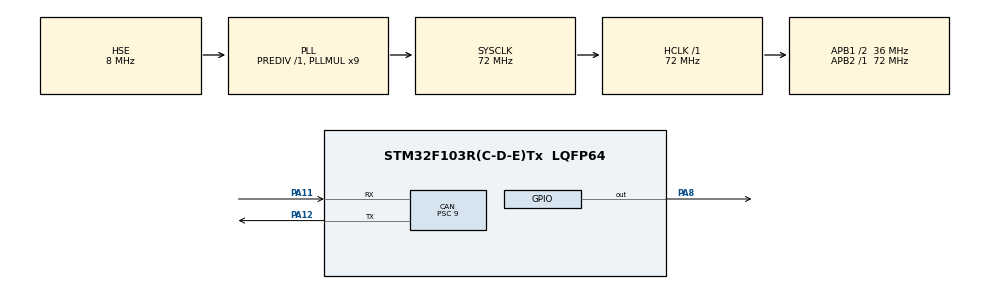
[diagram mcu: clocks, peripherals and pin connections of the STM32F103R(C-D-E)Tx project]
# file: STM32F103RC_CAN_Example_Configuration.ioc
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CAN.ABOM=ENABLE
CAN.AWUM=ENABLE
CAN.BS1=CAN_BS1_5TQ
CAN.BS2=CAN_BS2_2TQ
CAN.CalculateBaudRate=500000
CAN.CalculateTimeBit=2000
CAN.CalculateTimeQuantum=250.0
CAN.NART=ENABLE
CAN.Prescaler=9
Mcu.Family=STM32F1
Mcu.Name=STM32F103R(C-D-E)Tx
Mcu.Package=LQFP64
NVIC.PriorityGroup=NVIC_PRIORITYGROUP_4
NVIC.USB_LP_CAN1_RX0_IRQn=true\:0\:0\:false\:false\:true\:true\:true\:true
PA11.Mode=CAN_Activate
PA11.Signal=CAN_RX
PA12.Mode=CAN_Activate
PA12.Signal=CAN_TX
PA13.Mode=Trace_Asynchronous_SW
PA13.Signal=SYS_JTMS-SWDIO
PA14.Mode=Trace_Asynchronous_SW
PA14.Signal=SYS_JTCK-SWCLK
PA8.Signal=GPIO_Output
PB3.Mode=Trace_Asynchronous_SW
PB3.Signal=SYS_JTDO-TRACESWO
PD0-OSC_IN.Mode=HSE-External-Oscillator
PD0-OSC_IN.Signal=RCC_OSC_IN
PD1-OSC_OUT.Mode=HSE-External-Oscillator
PD1-OSC_OUT.Signal=RCC_OSC_OUT
ProjectManager.HeapSize=0x200
ProjectManager.StackSize=0x400
ProjectManager.TargetToolchain=MDK-ARM V5.32
RCC.AHBFreq_Value=72000000
RCC.APB1CLKDivider=RCC_HCLK_DIV2
RCC.APB1Freq_Value=36000000
RCC.APB1TimFreq_Value=72000000
RCC.APB2Freq_Value=72000000
RCC.APB2TimFreq_Value=72000000
RCC.HCLKFreq_Value=72000000
RCC.PLLMUL=RCC_PLL_MUL9
RCC.PLLSourceVirtual=RCC_PLLSOURCE_HSE
RCC.SYSCLKFreq_VALUE=72000000
RCC.SYSCLKSource=RCC_SYSCLKSOURCE_PLLCLK
RCC.USBFreq_Value=72000000
board=custom

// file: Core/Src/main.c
/* USER CODE BEGIN Header */
/**
  ******************************************************************************
  * @file           : main.c
  * @brief          : Main program body
  ******************************************************************************
  * @attention
  *
  * Copyright (c) 2023 STMicroelectronics.
  * All rights reserved.
  *
  * This software is licensed under terms that can be found in the LICENSE file
  * in the root directory of this software component.
  * If no LICENSE file comes with this software, it is provided AS-IS.
  *
  ******************************************************************************
  */
/* USER CODE END Header */
#include "main.h"

/* USER CODE BEGIN Includes */
#include"CAN_SignalHandler.h"
CAN_TxHeaderTypeDef   TxHeader;

uint8_t               TxData[8] = {0,0,0,0,0,0,0,0};

uint32_t              TxMailbox;

CAN_RxHeaderTypeDef   RxHeader;

CAN_FilterTypeDef	  canfil;

uint8_t               RxData[8] = {0,0,0,0,0,0,0,0};

uint16_t datacheck[75]={0};
uint16_t previousData[75]={0};
uint16_t data1,data2,data3;
/* USER CODE END Includes */

CAN_HandleTypeDef hcan;

/* USER CODE BEGIN PV */
void HAL_CAN_RxFifo0MsgPendingCallback(CAN_HandleTypeDef *hcan1)
{

//		HAL_CAN_GetRxMessage(hcan1, CAN_RX_FIFO0, &RxHeader, RxData);
//		for (int i = 0; i < 8; i++) {
//			TxData[i]=RxData[i];
//		}
//		HAL_CAN_AddTxMessage(&hcan, &TxHeader, TxData, &TxMailbox);
//		HAL_GPIO_TogglePin(GPIOA, GPIO_PIN_8);

	HAL_CAN_GetRxMessage(hcan1, CAN_RX_FIFO0, &RxHeader, RxData);
	int8_t msg_Idx = MessageIdx(RxHeader.StdId);
	StoreSignal(msg_Idx, RxData);
	//HAL_CAN_AddTxMessage(&hcan, &TxHeader, TxData, &TxMailbox);
}

/* USER CODE END PV */

void SystemClock_Config(void);
static void MX_GPIO_Init(void);
static void MX_CAN_Init(void);

int main(void)
{
  /* USER CODE BEGIN 1 */
	/*Filter congiguration*/
	canfil.FilterBank = 0;
	canfil.FilterMode = CAN_FILTERMODE_IDMASK;
	canfil.FilterFIFOAssignment = CAN_RX_FIFO0;
	canfil.FilterIdHigh = 0;
	canfil.FilterIdLow = 0;
	canfil.FilterMaskIdHigh = 0;
	canfil.FilterMaskIdLow = 0;
	canfil.FilterScale = CAN_FILTERSCALE_32BIT;
	canfil.FilterActivation = ENABLE;
	canfil.SlaveStartFilterBank = 14;
	/*TxHeader Configuration*/
	TxHeader.IDE = CAN_ID_STD;
	TxHeader.StdId = 0x446;
	TxHeader.RTR = CAN_RTR_DATA;
	TxHeader.DLC = 8;
	TxHeader.TransmitGlobalTime = DISABLE;

  /* USER CODE END 1 */

  /* MCU Configuration--------------------------------------------------------*/

  /* Reset of all peripherals, Initializes the Flash interface and the Systick. */
  HAL_Init();

  /* Configure the system clock */
  SystemClock_Config();

  /* Initialize all configured peripherals */
  MX_GPIO_Init();
  MX_CAN_Init();
  /* USER CODE BEGIN 2 */
  HAL_CAN_ConfigFilter(&hcan,&canfil); //Initialize CAN Filter
  HAL_CAN_Start(&hcan);
  HAL_CAN_ActivateNotification(&hcan,CAN_IT_RX_FIFO0_MSG_PENDING);// Initialize
  /* USER CODE END 2 */

  /* Infinite loop */
  /* USER CODE BEGIN WHILE */
  while (1)
  {
		//ReadCanSignal8(69,&datacheck[2]);

		//ReadCanSignal8(70,&datacheck[3]);

		//ReadCanSignal8(71,&datacheck[4]);

//		ReadCanSignal8(71,&data3);
//		HAL_Delay(50);
//		ReadCanSignal8(69,&data1);
//		HAL_Delay(50);
//		ReadCanSignal8(70,&data2);
//		HAL_Delay(50);
		for(int i =0;i<75;i++)
		{
			ReadCanSignal8(i+1,&datacheck[i]);
			HAL_Delay(50);
		}

		for(int i =0;i<75;i++)
		{
			if(previousData[i] != datacheck[i])
			{
				TxHeader.StdId = getSignal_MessageId(i)+0x11;
				getSignalMessageData(i, TxData,datacheck[i]);
				HAL_CAN_AddTxMessage(&hcan, &TxHeader, TxData, &TxMailbox);
				HAL_Delay(50);
				previousData[i] = datacheck[i];
			}
		}

//	 	 HAL_GPIO_TogglePin(GPIOA,GPIO_PIN_8);
//	 	 HAL_CAN_AddTxMessage(&hcan, &TxHeader, TxData, &TxMailbox);
//	 	 HAL_Delay(500);

    /* USER CODE END WHILE */

  }
}

void SystemClock_Config(void)
{
  RCC_OscInitTypeDef RCC_OscInitStruct = {0};
  RCC_ClkInitTypeDef RCC_ClkInitStruct = {0};

  /** Initializes the RCC Oscillators according to the specified parameters
  * in the RCC_OscInitTypeDef structure.
  */
  RCC_OscInitStruct.OscillatorType = RCC_OSCILLATORTYPE_HSE;
  RCC_OscInitStruct.HSEState = RCC_HSE_ON;
  RCC_OscInitStruct.HSEPredivValue = RCC_HSE_PREDIV_DIV1;
  RCC_OscInitStruct.HSIState = RCC_HSI_ON;
  RCC_OscInitStruct.PLL.PLLState = RCC_PLL_ON;
  RCC_OscInitStruct.PLL.PLLSource = RCC_PLLSOURCE_HSE;
  RCC_OscInitStruct.PLL.PLLMUL = RCC_PLL_MUL9;
  if (HAL_RCC_OscConfig(&RCC_OscInitStruct) != HAL_OK)
  {
    Error_Handler();
  }

  /** Initializes the CPU, AHB and APB buses clocks
  */
  RCC_ClkInitStruct.ClockType = RCC_CLOCKTYPE_HCLK|RCC_CLOCKTYPE_SYSCLK
                              |RCC_CLOCKTYPE_PCLK1|RCC_CLOCKTYPE_PCLK2;
  RCC_ClkInitStruct.SYSCLKSource = RCC_SYSCLKSOURCE_PLLCLK;
  RCC_ClkInitStruct.AHBCLKDivider = RCC_SYSCLK_DIV1;
  RCC_ClkInitStruct.APB1CLKDivider = RCC_HCLK_DIV2;
  RCC_ClkInitStruct.APB2CLKDivider = RCC_HCLK_DIV1;

  if (HAL_RCC_ClockConfig(&RCC_ClkInitStruct, FLASH_LATENCY_2) != HAL_OK)
  {
    Error_Handler();
  }
}

static void MX_CAN_Init(void)
{

  hcan.Instance = CAN1;
  hcan.Init.Prescaler = 9;
  hcan.Init.Mode = CAN_MODE_NORMAL;
  hcan.Init.SyncJumpWidth = CAN_SJW_1TQ;
  hcan.Init.TimeSeg1 = CAN_BS1_5TQ;
  hcan.Init.TimeSeg2 = CAN_BS2_2TQ;
  hcan.Init.TimeTriggeredMode = DISABLE;
  hcan.Init.AutoBusOff = ENABLE;
  hcan.Init.AutoWakeUp = ENABLE;
  hcan.Init.AutoRetransmission = ENABLE;
  hcan.Init.ReceiveFifoLocked = DISABLE;
  hcan.Init.TransmitFifoPriority = DISABLE;
  if (HAL_CAN_Init(&hcan) != HAL_OK)
  {
    Error_Handler();
  }

}

static void MX_GPIO_Init(void)
{
  GPIO_InitTypeDef GPIO_InitStruct = {0};

  /* GPIO Ports Clock Enable */
  __HAL_RCC_GPIOD_CLK_ENABLE();
  __HAL_RCC_GPIOA_CLK_ENABLE();
  __HAL_RCC_GPIOB_CLK_ENABLE();

  /*Configure GPIO pin Output Level */
  HAL_GPIO_WritePin(GPIOA, GPIO_PIN_8, GPIO_PIN_RESET);

  /*Configure GPIO pin : PA8 */
  GPIO_InitStruct.Pin = GPIO_PIN_8;
  GPIO_InitStruct.Mode = GPIO_MODE_OUTPUT_PP;
  GPIO_InitStruct.Pull = GPIO_NOPULL;
  GPIO_InitStruct.Speed = GPIO_SPEED_FREQ_LOW;
  HAL_GPIO_Init(GPIOA, &GPIO_InitStruct);

}

void Error_Handler(void)
{
  __disable_irq();
  while (1)
  {
  }
}
